# CY8C4248AZI_L475 register map
File version: 0.1
Registers are 32-bit, read-write, no defined reset value unless marked. A register's access mark holds for its fields unless they carry their own. Offsets are from the block's base; [hi:lo] are bit positions; 'fields as' and 'values as' point back to an identical list.

## SRV3
Base 0x00000000
0x400F0022 SRV3_COMPARE_1 16-bit — UDB.D0 - Assigned Compare1 Value
0x400F0032 SRV3_COMPARE_2 16-bit — UDB.D1 - Assigned Compare2 Value
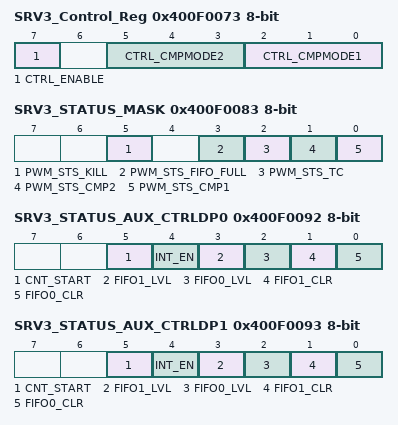
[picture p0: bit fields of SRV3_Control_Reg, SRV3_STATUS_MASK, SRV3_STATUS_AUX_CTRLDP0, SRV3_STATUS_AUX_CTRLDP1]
0x400F0073 SRV3_Control_Reg 8-bit — UDB Control Register - Assigned Control Register Value
  [7] CTRL_ENABLE — Enable the PWM
  [5:3] CTRL_CMPMODE2 — Compare mode 2
  [2:0] CTRL_CMPMODE1 — Compare mode 1
0x400F0083 SRV3_STATUS_MASK 8-bit — UDB Status bits Interrupt Mask Enable Register
  [5] PWM_STS_KILL ro — Enables the Interrupt on Kill
  [3] PWM_STS_FIFO_FULL ro — FIFO Full Status Mask
  [2] PWM_STS_TC ro — Enables the Interrupt on Terminal Count
  [1] PWM_STS_CMP2 ro — Enables the Interrupt on Compare 2
  [0] PWM_STS_CMP1 ro — Enables the Interrupt on Compare 1
0x400F0092 SRV3_STATUS_AUX_CTRLDP0 8-bit — UDB Auxilliary Control Register
  [5] CNT_START — FIFO0 clear
    0=E_CNT_START0 (Disable counter); 1=E_CNT_START1 (Enable counter)
  [4] INT_EN
    0=E_INT_EN0 (Interrupt disabled); 1=E_INT_EN1 (Interrupt enabled)
  [3] FIFO1_LVL — FIFO level
    0=E_FIFO_LVL_0 (FIFO LVL: input mode: FIFO not full; output mode: FIFO not empty); 1=E_FIFO_LVL_1 (FIFO LVL: input mode: FIFO at least 1/2 empty; output mode: FIFO at least 1/2 full)
  [2] FIFO0_LVL — FIFO level
    values as FIFO1_LVL
  [1] FIFO1_CLR — FIFO1 clear
    0=E_FIFO_CLR_0 (Normal FIFO operation); 1=E_FIFO_CLR_1 (Clear FIFO state)
  [0] FIFO0_CLR — FIFO0 clear
    values as FIFO1_CLR
0x400F0093 SRV3_STATUS_AUX_CTRLDP1 8-bit — UDB Auxilliary Control Register
  fields as SRV3_STATUS_AUX_CTRLDP0

## SRV2
Base 0x00000000
0x400F0020 SRV2_COMPARE_1 16-bit — UDB.D0 - Assigned Compare1 Value
0x400F0030 SRV2_COMPARE_2 16-bit — UDB.D1 - Assigned Compare2 Value
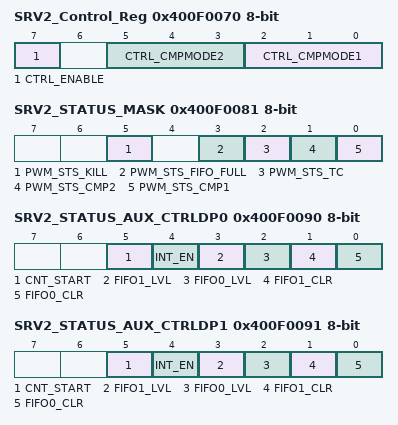
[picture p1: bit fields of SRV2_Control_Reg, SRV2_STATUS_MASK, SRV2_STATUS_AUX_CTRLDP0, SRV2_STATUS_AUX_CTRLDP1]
0x400F0070 SRV2_Control_Reg 8-bit — UDB Control Register - Assigned Control Register Value
  [7] CTRL_ENABLE — Enable the PWM
  [5:3] CTRL_CMPMODE2 — Compare mode 2
  [2:0] CTRL_CMPMODE1 — Compare mode 1
0x400F0081 SRV2_STATUS_MASK 8-bit — UDB Status bits Interrupt Mask Enable Register
  [5] PWM_STS_KILL ro — Enables the Interrupt on Kill
  [3] PWM_STS_FIFO_FULL ro — FIFO Full Status Mask
  [2] PWM_STS_TC ro — Enables the Interrupt on Terminal Count
  [1] PWM_STS_CMP2 ro — Enables the Interrupt on Compare 2
  [0] PWM_STS_CMP1 ro — Enables the Interrupt on Compare 1
0x400F0090 SRV2_STATUS_AUX_CTRLDP0 8-bit — UDB Auxilliary Control Register
  [5] CNT_START — FIFO0 clear
    0=E_CNT_START0 (Disable counter); 1=E_CNT_START1 (Enable counter)
  [4] INT_EN
    0=E_INT_EN0 (Interrupt disabled); 1=E_INT_EN1 (Interrupt enabled)
  [3] FIFO1_LVL — FIFO level
    0=E_FIFO_LVL_0 (FIFO LVL: input mode: FIFO not full; output mode: FIFO not empty); 1=E_FIFO_LVL_1 (FIFO LVL: input mode: FIFO at least 1/2 empty; output mode: FIFO at least 1/2 full)
  [2] FIFO0_LVL — FIFO level
    values as FIFO1_LVL
  [1] FIFO1_CLR — FIFO1 clear
    0=E_FIFO_CLR_0 (Normal FIFO operation); 1=E_FIFO_CLR_1 (Clear FIFO state)
  [0] FIFO0_CLR — FIFO0 clear
    values as FIFO1_CLR
0x400F0091 SRV2_STATUS_AUX_CTRLDP1 8-bit — UDB Auxilliary Control Register
  fields as SRV2_STATUS_AUX_CTRLDP0

## M3PWM
Base 0x00000000
0x402001C8 COUNTER — Current counter value
0x402001CC CC — Compare / capture value
0x402001D0 CC_BUF — Compare / capture buffer value
0x402001D4 PERIOD — Period value
0x402001D8 PERIOD_BUF — Period buffer value

## SRV1
Base 0x00000000
0x400F0026 SRV1_COMPARE_1 16-bit — UDB.D0 - Assigned Compare1 Value
0x400F0036 SRV1_COMPARE_2 16-bit — UDB.D1 - Assigned Compare2 Value
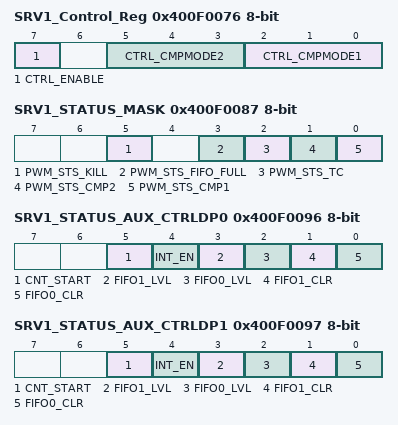
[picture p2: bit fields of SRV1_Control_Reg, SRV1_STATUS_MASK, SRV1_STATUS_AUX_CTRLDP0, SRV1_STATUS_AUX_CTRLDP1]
0x400F0076 SRV1_Control_Reg 8-bit — UDB Control Register - Assigned Control Register Value
  [7] CTRL_ENABLE — Enable the PWM
  [5:3] CTRL_CMPMODE2 — Compare mode 2
  [2:0] CTRL_CMPMODE1 — Compare mode 1
0x400F0087 SRV1_STATUS_MASK 8-bit — UDB Status bits Interrupt Mask Enable Register
  [5] PWM_STS_KILL ro — Enables the Interrupt on Kill
  [3] PWM_STS_FIFO_FULL ro — FIFO Full Status Mask
  [2] PWM_STS_TC ro — Enables the Interrupt on Terminal Count
  [1] PWM_STS_CMP2 ro — Enables the Interrupt on Compare 2
  [0] PWM_STS_CMP1 ro — Enables the Interrupt on Compare 1
0x400F0096 SRV1_STATUS_AUX_CTRLDP0 8-bit — UDB Auxilliary Control Register
  [5] CNT_START — FIFO0 clear
    0=E_CNT_START0 (Disable counter); 1=E_CNT_START1 (Enable counter)
  [4] INT_EN
    0=E_INT_EN0 (Interrupt disabled); 1=E_INT_EN1 (Interrupt enabled)
  [3] FIFO1_LVL — FIFO level
    0=E_FIFO_LVL_0 (FIFO LVL: input mode: FIFO not full; output mode: FIFO not empty); 1=E_FIFO_LVL_1 (FIFO LVL: input mode: FIFO at least 1/2 empty; output mode: FIFO at least 1/2 full)
  [2] FIFO0_LVL — FIFO level
    values as FIFO1_LVL
  [1] FIFO1_CLR — FIFO1 clear
    0=E_FIFO_CLR_0 (Normal FIFO operation); 1=E_FIFO_CLR_1 (Clear FIFO state)
  [0] FIFO0_CLR — FIFO0 clear
    values as FIFO1_CLR
0x400F0097 SRV1_STATUS_AUX_CTRLDP1 8-bit — UDB Auxilliary Control Register
  fields as SRV1_STATUS_AUX_CTRLDP0
